AUTOSAR XML (schema 00046)
package /ComponentTypes
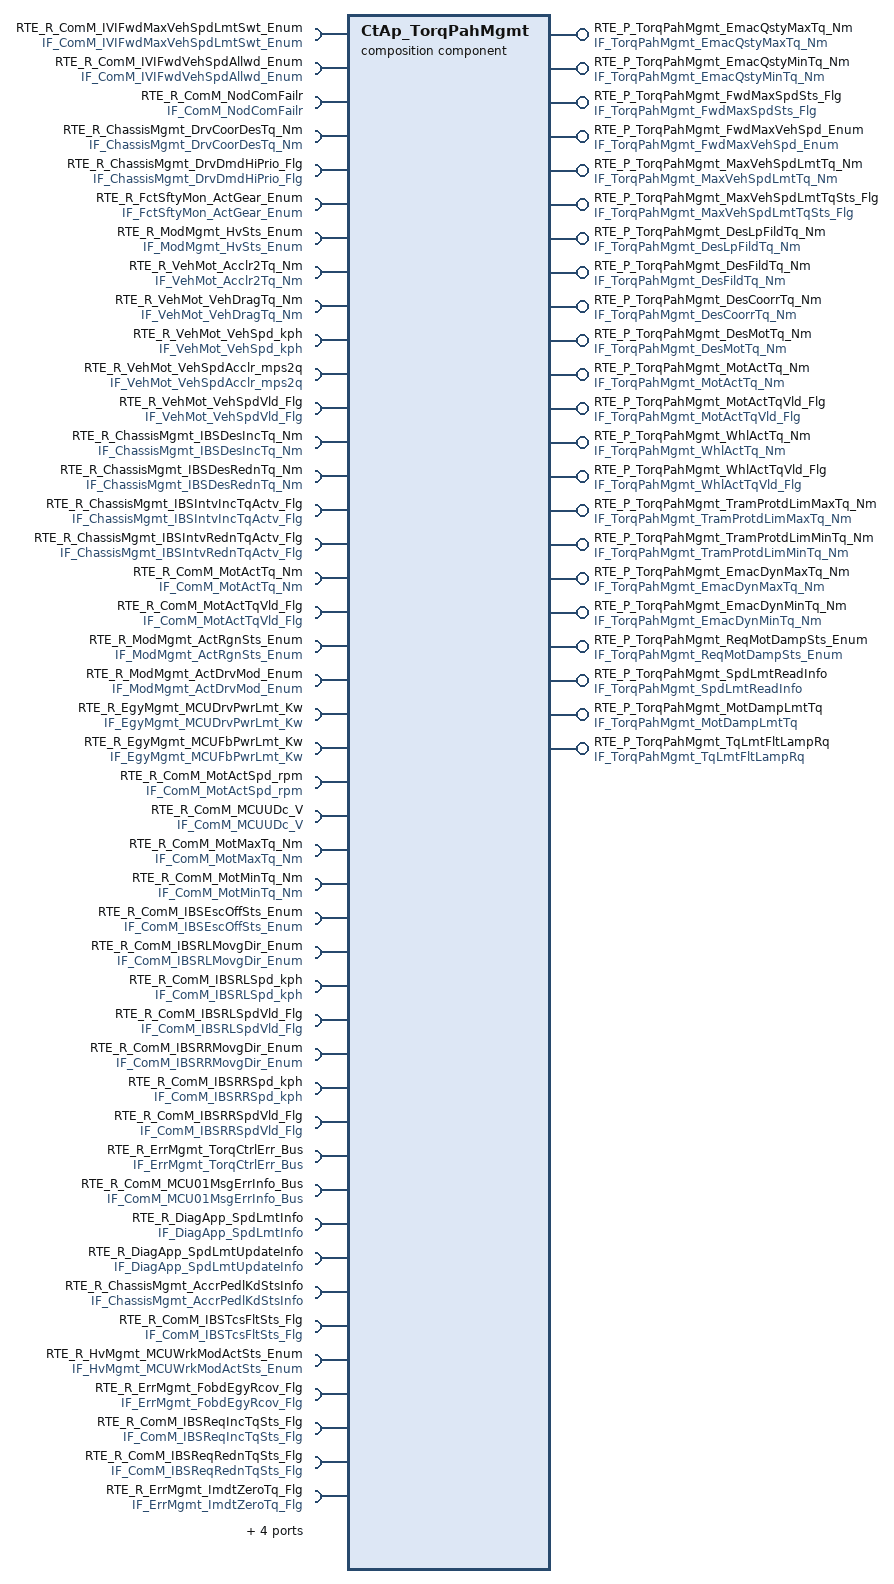
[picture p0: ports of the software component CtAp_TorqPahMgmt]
  composition sw component type CtAp_TorqPahMgmt
    require port RTE_R_ComM_IVIFwdMaxVehSpdLmtSwt_Enum: nonqueued-receiver-com-spec{data-element=tec_ComM_IVIFwdMaxVehSpdLmtSwt_Enum, filter=data-filter-type=ALWAYS, init-value=0}, required-interface=IF_ComM_IVIFwdMaxVehSpdLmtSwt_Enum
    require port RTE_R_ComM_IVIFwdVehSpdAllwd_Enum: nonqueued-receiver-com-spec{data-element=tec_ComM_IVIFwdVehSpdAllwd_Enum, filter=data-filter-type=ALWAYS, init-value=0}, required-interface=IF_ComM_IVIFwdVehSpdAllwd_Enum
    require port RTE_R_ComM_NodComFailr: required-interface=IF_ComM_NodComFailr
      required-com-specs:
        data-element=tec_ComM_SGWNodComFailr_Flg, filter=data-filter-type=ALWAYS, init-value=0
        data-element=tec_ComM_CGWNodComFailr_Flg, filter=data-filter-type=ALWAYS, init-value=0
        data-element=tec_ComM_TCUNodComFailr_Flg, filter=data-filter-type=ALWAYS, init-value=0
        data-element=tec_ComM_BCMNodComFailr_Flg, filter=data-filter-type=ALWAYS, init-value=0
        data-element=tec_ComM_PRNDNodComFailr_Flg, filter=data-filter-type=ALWAYS, init-value=0
        data-element=tec_ComM_IVINodComFailr_Flg, filter=data-filter-type=ALWAYS, init-value=0
        data-element=tec_ComM_DCDCNodComFailr_Flg, filter=data-filter-type=ALWAYS, init-value=0
        data-element=tec_ComM_OBCNodComFailr_Flg, filter=data-filter-type=ALWAYS, init-value=0
        data-element=tec_ComM_CHIBSNodComFailr_Flg, filter=data-filter-type=ALWAYS, init-value=0
        data-element=tec_ComM_MCUNodComFailr_Flg, filter=data-filter-type=ALWAYS, init-value=0
        data-element=tec_ComM_EVCOMNodComFailr_Flg, filter=data-filter-type=ALWAYS, init-value=0
        data-element=tec_ComM_EPTIBSNodComFailr_Flg, filter=data-filter-type=ALWAYS, init-value=0
        data-element=tec_ComM_DCMNodComFailr_Flg, filter=data-filter-type=ALWAYS, init-value=0
        data-element=tec_ComM_BMSNodComFailr_Flg, filter=data-filter-type=ALWAYS, init-value=0
        data-element=tec_ComM_ACUNodComFailr_Flg, filter=data-filter-type=ALWAYS, init-value=0
        data-element=tec_ComM_APTCNodComFailr_Flg, filter=data-filter-type=ALWAYS, init-value=0
        data-element=tec_ComM_ADCUNodComFailr_Flg, filter=data-filter-type=ALWAYS, init-value=0
        data-element=tec_ComM_DCMRRNodComFailr_Flg, filter=data-filter-type=ALWAYS, init-value=0
        data-element=tec_ComM_DCMRLNodComFailr_Flg, filter=data-filter-type=ALWAYS, init-value=0
        data-element=tec_ComM_DCMFRNodComFailr_Flg, filter=data-filter-type=ALWAYS, init-value=0
        data-element=tec_ComM_DCMFLNodComFailr_Flg, filter=data-filter-type=ALWAYS, init-value=0
        data-element=tec_ComM_SGWCHNodComFailr_Flg, filter=data-filter-type=ALWAYS, init-value=0
    7 x provide port:
      RTE_P_TorqPahMgmt_EmacQstyMaxTq_Nm: nonqueued-sender-com-spec{data-element=tec_TorqPahMgmt_EmacQstyMaxTq_Nm, init-value=0}, provided-interface=IF_TorqPahMgmt_EmacQstyMaxTq_Nm
      RTE_P_TorqPahMgmt_EmacQstyMinTq_Nm: nonqueued-sender-com-spec{data-element=tec_TorqPahMgmt_EmacQstyMinTq_Nm, init-value=0}, provided-interface=IF_TorqPahMgmt_EmacQstyMinTq_Nm
      RTE_P_TorqPahMgmt_FwdMaxSpdSts_Flg: nonqueued-sender-com-spec{data-element=tec_TorqPahMgmt_FwdMaxSpdSts_Flg, init-value=0}, provided-interface=IF_TorqPahMgmt_FwdMaxSpdSts_Flg
      RTE_P_TorqPahMgmt_FwdMaxVehSpd_Enum: nonqueued-sender-com-spec{data-element=tec_TorqPahMgmt_FwdMaxVehSpd_Enum, init-value=0}, provided-interface=IF_TorqPahMgmt_FwdMaxVehSpd_Enum
      RTE_P_TorqPahMgmt_MaxVehSpdLmtTq_Nm: nonqueued-sender-com-spec{data-element=tec_TorqPahMgmt_MaxVehSpdLmtTq_Nm, init-value=0}, provided-interface=IF_TorqPahMgmt_MaxVehSpdLmtTq_Nm
      RTE_P_TorqPahMgmt_MaxVehSpdLmtTqSts_Flg: nonqueued-sender-com-spec{data-element=tec_TorqPahMgmt_MaxVehSpdLmtTqSts_Flg, init-value=0}, provided-interface=IF_TorqPahMgmt_MaxVehSpdLmtTqSts_Flg
      RTE_P_TorqPahMgmt_DesLpFildTq_Nm: nonqueued-sender-com-spec{data-element=tec_TorqPahMgmt_DesLpFildTq_Nm, init-value=0}, provided-interface=IF_TorqPahMgmt_DesLpFildTq_Nm
    9 x require port:
      RTE_R_ChassisMgmt_DrvCoorDesTq_Nm: nonqueued-receiver-com-spec{data-element=tec_ChassisMgmt_DrvCoorrDesTq_Nm, filter=data-filter-type=ALWAYS, init-value=0}, required-interface=IF_ChassisMgmt_DrvCoorDesTq_Nm
      RTE_R_ChassisMgmt_DrvDmdHiPrio_Flg: nonqueued-receiver-com-spec{data-element=tec_ChassisMgmt_DrvDmdHiPrio_Flg, filter=data-filter-type=ALWAYS, init-value=0}, required-interface=IF_ChassisMgmt_DrvDmdHiPrio_Flg
      RTE_R_FctSftyMon_ActGear_Enum: nonqueued-receiver-com-spec{data-element=tec_FctSftyMon_ActGear_Enum, filter=data-filter-type=ALWAYS, init-value=0}, required-interface=IF_FctSftyMon_ActGear_Enum
      RTE_R_ModMgmt_HvSts_Enum: nonqueued-receiver-com-spec{data-element=tec_ModMgmt_HvSts_Enum, filter=data-filter-type=ALWAYS, init-value=0}, required-interface=IF_ModMgmt_HvSts_Enum
      RTE_R_VehMot_Acclr2Tq_Nm: nonqueued-receiver-com-spec{data-element=tec_VehMot_Acclr2Tq_Nm, filter=data-filter-type=ALWAYS, init-value=0}, required-interface=IF_VehMot_Acclr2Tq_Nm
      RTE_R_VehMot_VehDragTq_Nm: nonqueued-receiver-com-spec{data-element=tec_VehMot_VehDragTq_Nm, filter=data-filter-type=ALWAYS, init-value=0}, required-interface=IF_VehMot_VehDragTq_Nm
      RTE_R_VehMot_VehSpd_kph: nonqueued-receiver-com-spec{data-element=tec_VehMot_VehSpd_kph, filter=data-filter-type=ALWAYS, init-value=0}, required-interface=IF_VehMot_VehSpd_kph
      RTE_R_VehMot_VehSpdAcclr_mps2q: nonqueued-receiver-com-spec{data-element=tec_VehMot_VehSpdAcclr_mps2q, filter=data-filter-type=ALWAYS, init-value=0}, required-interface=IF_VehMot_VehSpdAcclr_mps2q
      RTE_R_VehMot_VehSpdVld_Flg: nonqueued-receiver-com-spec{data-element=tec_VehMot_VehSpdVld_Flg, filter=data-filter-type=ALWAYS, init-value=0}, required-interface=IF_VehMot_VehSpdVld_Flg
    provide port RTE_P_TorqPahMgmt_DesFildTq_Nm: nonqueued-sender-com-spec{data-element=tec_TorqPahMgmt_DesFildTq_Nm, init-value=0}, provided-interface=IF_TorqPahMgmt_DesFildTq_Nm
    4 x require port:
      RTE_R_ChassisMgmt_IBSDesIncTq_Nm: nonqueued-receiver-com-spec{data-element=tec_ChassisMgmt_IBSDesIncTq_Nm, filter=data-filter-type=ALWAYS, init-value=0}, required-interface=IF_ChassisMgmt_IBSDesIncTq_Nm
      RTE_R_ChassisMgmt_IBSDesRednTq_Nm: nonqueued-receiver-com-spec{data-element=tec_ChassisMgmt_IBSDesRednTq_Nm, filter=data-filter-type=ALWAYS, init-value=0}, required-interface=IF_ChassisMgmt_IBSDesRednTq_Nm
      RTE_R_ChassisMgmt_IBSIntvIncTqActv_Flg: nonqueued-receiver-com-spec{data-element=tec_ChassisMgmt_IBSIntvIncTqActv_Flg, filter=data-filter-type=ALWAYS, init-value=0}, required-interface=IF_ChassisMgmt_IBSIntvIncTqActv_Flg
      RTE_R_ChassisMgmt_IBSIntvRednTqActv_Flg: nonqueued-receiver-com-spec{data-element=tec_ChassisMgmt_IBSIntvRednTqActv_Flg, filter=data-filter-type=ALWAYS, init-value=0}, required-interface=IF_ChassisMgmt_IBSIntvRednTqActv_Flg
    provide port RTE_P_TorqPahMgmt_DesCoorrTq_Nm: nonqueued-sender-com-spec{data-element=tec_TorqPahMgmt_DesCoorrTq_Nm, init-value=0}, provided-interface=IF_TorqPahMgmt_DesCoorrTq_Nm
    4 x require port:
      RTE_R_ComM_MotActTq_Nm: nonqueued-receiver-com-spec{data-element=tec_ComM_MotActTq_Nm, filter=data-filter-type=ALWAYS, init-value=0}, required-interface=IF_ComM_MotActTq_Nm
      RTE_R_ComM_MotActTqVld_Flg: nonqueued-receiver-com-spec{data-element=tec_ComM_MotActTqVld_Flg, filter=data-filter-type=ALWAYS, init-value=0}, required-interface=IF_ComM_MotActTqVld_Flg
      RTE_R_ModMgmt_ActRgnSts_Enum: nonqueued-receiver-com-spec{data-element=tec_ModMgmt_ActRgnSts_Enum, filter=data-filter-type=ALWAYS, init-value=0}, required-interface=IF_ModMgmt_ActRgnSts_Enum
      RTE_R_ModMgmt_ActDrvMod_Enum: nonqueued-receiver-com-spec{data-element=tec_ModMgmt_ActDrvMod_Enum, filter=data-filter-type=ALWAYS, init-value=0}, required-interface=IF_ModMgmt_ActDrvMod_Enum
    5 x provide port:
      RTE_P_TorqPahMgmt_DesMotTq_Nm: nonqueued-sender-com-spec{data-element=tec_TorqPahMgmt_DesMotTq_Nm, init-value=0}, provided-interface=IF_TorqPahMgmt_DesMotTq_Nm
      RTE_P_TorqPahMgmt_MotActTq_Nm: nonqueued-sender-com-spec{data-element=tec_TorqPahMgmt_MotActTq_Nm, init-value=0}, provided-interface=IF_TorqPahMgmt_MotActTq_Nm
      RTE_P_TorqPahMgmt_MotActTqVld_Flg: nonqueued-sender-com-spec{data-element=tec_TorqPahMgmt_MotActTqVld_Flg, init-value=0}, provided-interface=IF_TorqPahMgmt_MotActTqVld_Flg
      RTE_P_TorqPahMgmt_WhlActTq_Nm: nonqueued-sender-com-spec{data-element=tec_TorqPahMgmt_WhlActTq_Nm, init-value=0}, provided-interface=IF_TorqPahMgmt_WhlActTq_Nm
      RTE_P_TorqPahMgmt_WhlActTqVld_Flg: nonqueued-sender-com-spec{data-element=tec_TorqPahMgmt_WhlActTqVld_Flg, init-value=0}, provided-interface=IF_TorqPahMgmt_WhlActTqVld_Flg
    6 x require port:
      RTE_R_EgyMgmt_MCUDrvPwrLmt_Kw: nonqueued-receiver-com-spec{data-element=tec_EgyMgmt_MCUDrvPwrLmt_Kw, filter=data-filter-type=ALWAYS, init-value=0}, required-interface=IF_EgyMgmt_MCUDrvPwrLmt_Kw
      RTE_R_EgyMgmt_MCUFbPwrLmt_Kw: nonqueued-receiver-com-spec{data-element=tec_EgyMgmt_MCUFbPwrLmt_Kw, filter=data-filter-type=ALWAYS, init-value=0}, required-interface=IF_EgyMgmt_MCUFbPwrLmt_Kw
      RTE_R_ComM_MotActSpd_rpm: nonqueued-receiver-com-spec{data-element=tec_ComM_MotActSpd_rpm, filter=data-filter-type=ALWAYS, init-value=0}, required-interface=IF_ComM_MotActSpd_rpm
      RTE_R_ComM_MCUUDc_V: nonqueued-receiver-com-spec{data-element=tec_ComM_MCUUDc_V, filter=data-filter-type=ALWAYS, init-value=0}, required-interface=IF_ComM_MCUUDc_V
      RTE_R_ComM_MotMaxTq_Nm: nonqueued-receiver-com-spec{data-element=tec_ComM_MotMaxTq_Nm, filter=data-filter-type=ALWAYS, init-value=0}, required-interface=IF_ComM_MotMaxTq_Nm
      RTE_R_ComM_MotMinTq_Nm: nonqueued-receiver-com-spec{data-element=tec_ComM_MotMinTq_Nm, filter=data-filter-type=ALWAYS, init-value=0}, required-interface=IF_ComM_MotMinTq_Nm
    5 x provide port:
      RTE_P_TorqPahMgmt_TramProtdLimMaxTq_Nm: nonqueued-sender-com-spec{data-element=tec_TorqPahMgmt_TramProtdLmtMaxTq_Nm, init-value=0}, provided-interface=IF_TorqPahMgmt_TramProtdLimMaxTq_Nm
      RTE_P_TorqPahMgmt_TramProtdLimMinTq_Nm: nonqueued-sender-com-spec{data-element=tec_TorqPahMgmt_TramProtdLmtMinTq_Nm, init-value=0}, provided-interface=IF_TorqPahMgmt_TramProtdLimMinTq_Nm
      RTE_P_TorqPahMgmt_EmacDynMaxTq_Nm: nonqueued-sender-com-spec{data-element=tec_TorqPahMgmt_EmacDynMaxTq_Nm, init-value=0}, provided-interface=IF_TorqPahMgmt_EmacDynMaxTq_Nm
      RTE_P_TorqPahMgmt_EmacDynMinTq_Nm: nonqueued-sender-com-spec{data-element=tec_TorqPahMgmt_EmacDynMinTq_Nm, init-value=0}, provided-interface=IF_TorqPahMgmt_EmacDynMinTq_Nm
      RTE_P_TorqPahMgmt_ReqMotDampSts_Enum: nonqueued-sender-com-spec{data-element=tec_TorqPahMgmt_ReqMotDampSts_Enum, init-value=0}, provided-interface=IF_TorqPahMgmt_ReqMotDampSts_Enum
    10 x require port:
      RTE_R_ComM_IBSEscOffSts_Enum: nonqueued-receiver-com-spec{data-element=tec_ComM_IBSEscOffSts_Enum, filter=data-filter-type=ALWAYS, init-value=0}, required-interface=IF_ComM_IBSEscOffSts_Enum
      RTE_R_ComM_IBSRLMovgDir_Enum: nonqueued-receiver-com-spec{data-element=tec_ComM_IBSRLMovgDir_Enum, filter=data-filter-type=ALWAYS, init-value=0}, required-interface=IF_ComM_IBSRLMovgDir_Enum
      RTE_R_ComM_IBSRLSpd_kph: nonqueued-receiver-com-spec{data-element=tec_ComM_IBSRLSpd_kph, filter=data-filter-type=ALWAYS, init-value=0}, required-interface=IF_ComM_IBSRLSpd_kph
      RTE_R_ComM_IBSRLSpdVld_Flg: nonqueued-receiver-com-spec{data-element=tec_ComM_IBSRLSpdVld_Flg, filter=data-filter-type=ALWAYS, init-value=0}, required-interface=IF_ComM_IBSRLSpdVld_Flg
      RTE_R_ComM_IBSRRMovgDir_Enum: nonqueued-receiver-com-spec{data-element=tec_ComM_IBSRRMovgDir_Enum, filter=data-filter-type=ALWAYS, init-value=0}, required-interface=IF_ComM_IBSRRMovgDir_Enum
      RTE_R_ComM_IBSRRSpd_kph: nonqueued-receiver-com-spec{data-element=tec_ComM_IBSRRSpd_kph, filter=data-filter-type=ALWAYS, init-value=0}, required-interface=IF_ComM_IBSRRSpd_kph
      RTE_R_ComM_IBSRRSpdVld_Flg: nonqueued-receiver-com-spec{data-element=tec_ComM_IBSRRSpdVld_Flg, filter=data-filter-type=ALWAYS, init-value=0}, required-interface=IF_ComM_IBSRRSpdVld_Flg
      RTE_R_ErrMgmt_TorqCtrlErr_Bus: nonqueued-receiver-com-spec{data-element=tec_ErrMgmt_TorqCtrlErr_Bus, filter=data-filter-type=ALWAYS, init-value=fields=[ErrMgmt_DlyGrdtZeroTq_Flg:0, ErrMgmt_GrdtZeroTq_Flg:0, ErrMgmt_ImdtZeroTq_Flg:0, ErrMgmt_VehSpdLim_kph:0, ErrMgmt_VehSpdLimEna_Flg:0]}, required-interface=IF_ErrMgmt_TorqCtrlErr_Bus
      RTE_R_ComM_MCU01MsgErrInfo_Bus: required-interface=IF_ComM_MCU01MsgErrInfo_Bus
        required-com-specs:
          data-element=tec_ComM_MCU01TimeoutInfo_Bus, filter=data-filter-type=ALWAYS, init-value=fields=[ComM_MonStatMCU01TimeoutInfo:0, ComM_MonResMCU01TimeoutInfo:0, ComM_ErrStatMCU01TimeoutInfo:0, ComM_ErrResMCU01TimeoutInfo:0]
          data-element=tec_ComM_MCU01CRCDTCInfo_Bus, filter=data-filter-type=ALWAYS, init-value=fields=[ComM_MonStatMCU01CRCDTCErrorInfo:0, ComM_MonResMCU01CRCDTCErrorInfo:0, ComM_ErrStatMCU01CRCDTCErrorInfo:0, ComM_ErrResMCU01CRCDTCErrorInfo:0]
          data-element=tec_ComM_MCU01CRCInfo_Bus, filter=data-filter-type=ALWAYS, init-value=fields=[ComM_MonStatMCU01CRCErrorInfo:0, ComM_MonResMCU01CRCErrorInfo:0, ComM_ErrStatMCU01CRCErrorInfo:0, ComM_ErrResMCU01CRCErrorInfo:0]
          data-element=tec_ComM_MCU01TimeoutDTCInfo_Bus, filter=data-filter-type=ALWAYS, init-value=fields=[ComM_MonStatMCU01TimeoutDTCErrorInfo:0, ComM_MonResMCU01TimeoutDTCErrorInfo:0, ComM_ErrStatMCU01TimeoutDTCErrorInfo:0, ComM_ErrResMCU01TimeoutDTCErrorInfo:0]
          data-element=tec_ComM_MCU01E2ETimeoutInfo_Bus, filter=data-filter-type=ALWAYS, init-value=fields=[ComM_MonStatMCU01E2ETimeoutInfo:0, ComM_MonResMCU01E2ETimeoutInfo:0, ComM_ErrStatMCU01E2ETimeoutInfo:0, ComM_ErrResMCU01E2ETimeoutInfo:0]
      RTE_R_DiagApp_SpdLmtInfo: nonqueued-receiver-com-spec{data-element=tec_DiagApp_SpdLmtInfo, filter=data-filter-type=ALWAYS, init-value=0}, required-interface=IF_DiagApp_SpdLmtInfo
    provide port RTE_P_TorqPahMgmt_SpdLmtReadInfo: nonqueued-sender-com-spec{data-element=tec_TorqPahMgmt_SpdLmtReadInfo, init-value=0}, provided-interface=IF_TorqPahMgmt_SpdLmtReadInfo
    4 x require port:
      RTE_R_DiagApp_SpdLmtUpdateInfo: nonqueued-receiver-com-spec{data-element=tec_DiagApp_SpdLmtUpdateInfo, filter=data-filter-type=ALWAYS, init-value=0}, required-interface=IF_DiagApp_SpdLmtUpdateInfo
      RTE_R_ChassisMgmt_AccrPedlKdStsInfo: nonqueued-receiver-com-spec{data-element=tec_ChassisMgmt_AccrPedlKdStsInfo, filter=data-filter-type=ALWAYS, init-value=0}, required-interface=IF_ChassisMgmt_AccrPedlKdStsInfo
      RTE_R_ComM_IBSTcsFltSts_Flg: nonqueued-receiver-com-spec{data-element=tec_ComM_IBSTcsFltSts_Flg, filter=data-filter-type=ALWAYS, init-value=0}, required-interface=IF_ComM_IBSTcsFltSts_Flg
      RTE_R_HvMgmt_MCUWrkModActSts_Enum: nonqueued-receiver-com-spec{data-element=tec_HvMgmt_MCUWrkModActSts_Enum, filter=data-filter-type=ALWAYS, init-value=0}, required-interface=IF_HvMgmt_MCUWrkModActSts_Enum
    provide port RTE_P_TorqPahMgmt_MotDampLmtTq: nonqueued-sender-com-spec{data-element=tec_TorqPahMgmt_MotDampLmtTq, init-value=0}, provided-interface=IF_TorqPahMgmt_MotDampLmtTq
    8 x require port:
      RTE_R_ErrMgmt_FobdEgyRcov_Flg: nonqueued-receiver-com-spec{data-element=tec_ErrMgmt_FobdEgyRcov_Flg, filter=data-filter-type=ALWAYS, init-value=0}, required-interface=IF_ErrMgmt_FobdEgyRcov_Flg
      RTE_R_ComM_IBSReqIncTqSts_Flg: nonqueued-receiver-com-spec{data-element=tec_ComM_IBSReqIncTqSts_Flg, filter=data-filter-type=ALWAYS, init-value=0}, required-interface=IF_ComM_IBSReqIncTqSts_Flg
      RTE_R_ComM_IBSReqRednTqSts_Flg: nonqueued-receiver-com-spec{data-element=tec_ComM_IBSReqRednTqSts_Flg, filter=data-filter-type=ALWAYS, init-value=0}, required-interface=IF_ComM_IBSReqRednTqSts_Flg
      RTE_R_ErrMgmt_ImdtZeroTq_Flg: nonqueued-receiver-com-spec{data-element=tec_ErrMgmt_ImdtZeroTq_Flg, filter=data-filter-type=ALWAYS, init-value=0}, required-interface=IF_ErrMgmt_ImdtZeroTq_Flg
      RTE_R_FctSftyMon_TarGearPInhbTq: nonqueued-receiver-com-spec{data-element=tec_FctSftyMon_TarGearPInhbTq, filter=data-filter-type=ALWAYS, init-value=0}, required-interface=IF_FctSftyMon_TarGearPInhbTq
      RTE_R_ChassisMgmt_BrkRgnActv_Flg: nonqueued-receiver-com-spec{data-element=tec_ChassisMgmt_BrkRgnActv_Flg, filter=data-filter-type=ALWAYS}, required-interface=IF_ChassisMgmt_BrkRgnActv_Flg
      RTE_R_ChassisMgmt_IBSApsReqTqActv_Flg: nonqueued-receiver-com-spec{data-element=tec_ChassisMgmt_IBSApsReqTqActv_Flg, filter=data-filter-type=ALWAYS, init-value=0}, required-interface=IF_ChassisMgmt_IBSApsReqTqActv_Flg
      RTE_R_ChassisMgmt_IBSVlcReqTqActv_Flg: nonqueued-receiver-com-spec{data-element=tec_ChassisMgmt_IBSVlcReqTqActv_Flg, filter=data-filter-type=ALWAYS, init-value=0}, required-interface=IF_ChassisMgmt_IBSVlcReqTqActv_Flg
    provide port RTE_P_TorqPahMgmt_TqLmtFltLampRq: nonqueued-sender-com-spec{data-element=tec_TorqPahMgmt_TqLmtFltLampRq, init-value=0}, provided-interface=IF_TorqPahMgmt_TqLmtFltLampRq
    8 x component:
      CtAp_SpdLmt: type=CtAp_SpdLmt
      CtAp_TorqFil: type=CtAp_TorqFil
      CtAp_TorqCrossZr: type=CtAp_TorqCrossZr
      CtAp_TorqCoor: type=CtAp_TorqCoor
      CtAp_TorqDamp: type=CtAp_TorqDamp
      CtAp_TorqModMap: type=CtAp_TorqModMap
      CtAp_TrsmProtd: type=CtAp_TrsmProtd
      CtAp_TorqLmt: type=CtAp_TorqLmt
    delegate CtAp_SpdLmt.RTE_R_ComM_IVIFwdMaxVehSpdLmtSwt_Enum <-> outer port RTE_R_ComM_IVIFwdMaxVehSpdLmtSwt_Enum
    delegate CtAp_SpdLmt.RTE_R_ComM_IVIFwdVehSpdAllwd_Enum <-> outer port RTE_R_ComM_IVIFwdVehSpdAllwd_Enum
    delegate CtAp_SpdLmt.RTE_R_ComM_NodComFailr <-> outer port RTE_R_ComM_NodComFailr
    delegate CtAp_SpdLmt.RTE_R_FctSftyMon_ActGear_Enum <-> outer port RTE_R_FctSftyMon_ActGear_Enum
    delegate CtAp_SpdLmt.RTE_R_ModMgmt_HvSts_Enum <-> outer port RTE_R_ModMgmt_HvSts_Enum
    delegate CtAp_SpdLmt.RTE_R_VehMot_VehSpd_kph <-> outer port RTE_R_VehMot_VehSpd_kph
    delegate CtAp_SpdLmt.RTE_R_VehMot_VehDragTq_Nm <-> outer port RTE_R_VehMot_VehDragTq_Nm
    delegate CtAp_SpdLmt.RTE_R_VehMot_VehSpdVld_Flg <-> outer port RTE_R_VehMot_VehSpdVld_Flg
    delegate CtAp_SpdLmt.RTE_R_VehMot_Acclr2Tq_Nm <-> outer port RTE_R_VehMot_Acclr2Tq_Nm
    delegate CtAp_SpdLmt.RTE_R_VehMot_VehSpdAcclr_mps2q <-> outer port RTE_R_VehMot_VehSpdAcclr_mps2q
    delegate CtAp_SpdLmt.RTE_P_TorqPahMgmt_FwdMaxSpdSts_Flg <-> outer port RTE_P_TorqPahMgmt_FwdMaxSpdSts_Flg
    delegate CtAp_SpdLmt.RTE_P_TorqPahMgmt_FwdMaxVehSpd_Enum <-> outer port RTE_P_TorqPahMgmt_FwdMaxVehSpd_Enum
    delegate CtAp_SpdLmt.RTE_P_TorqPahMgmt_MaxVehSpdLmtTq_Nm <-> outer port RTE_P_TorqPahMgmt_MaxVehSpdLmtTq_Nm
    delegate CtAp_SpdLmt.RTE_P_TorqPahMgmt_MaxVehSpdLmtTqSts_Flg <-> outer port RTE_P_TorqPahMgmt_MaxVehSpdLmtTqSts_Flg
    delegate CtAp_TorqFil.RTE_R_ChassisMgmt_DrvCoorDesTq_Nm <-> outer port RTE_R_ChassisMgmt_DrvCoorDesTq_Nm
    delegate CtAp_TorqFil.RTE_R_ChassisMgmt_DrvDmdHiPrio_Flg <-> outer port RTE_R_ChassisMgmt_DrvDmdHiPrio_Flg
    delegate CtAp_TorqFil.RTE_P_TorqPahMgmt_DesLpFildTq_Nm <-> outer port RTE_P_TorqPahMgmt_DesLpFildTq_Nm
    delegate CtAp_TorqCrossZr.RTE_R_ChassisMgmt_DrvDmdHiPrio_Flg <-> outer port RTE_R_ChassisMgmt_DrvDmdHiPrio_Flg
    delegate CtAp_TorqCrossZr.RTE_R_ModMgmt_ActDrvMod_Enum <-> outer port RTE_R_ModMgmt_ActDrvMod_Enum
    delegate CtAp_TorqCrossZr.RTE_R_FctSftyMon_ActGear_Enum <-> outer port RTE_R_FctSftyMon_ActGear_Enum
    connect CtAp_TorqFil.RTE_P_TorqPahMgmt_DesLpFildTq_Nm -> CtAp_TorqCrossZr.RTE_R_TorqPahMgmt_DesLpFildTq_Nm
    delegate CtAp_TorqCrossZr.RTE_R_ModMgmt_ActRgnSts_Enum <-> outer port RTE_R_ModMgmt_ActRgnSts_Enum
    delegate CtAp_TorqCrossZr.RTE_R_VehMot_VehSpd_kph <-> outer port RTE_R_VehMot_VehSpd_kph
    delegate CtAp_TorqCoor.RTE_R_ChassisMgmt_IBSDesIncTq_Nm <-> outer port RTE_R_ChassisMgmt_IBSDesIncTq_Nm
    delegate CtAp_TorqCoor.RTE_R_ChassisMgmt_IBSIntvIncTqActv_Flg <-> outer port RTE_R_ChassisMgmt_IBSIntvIncTqActv_Flg
    delegate CtAp_TorqCoor.RTE_R_ChassisMgmt_IBSDesRednTq_Nm <-> outer port RTE_R_ChassisMgmt_IBSDesRednTq_Nm
    delegate CtAp_TorqCoor.RTE_R_ModMgmt_HvSts_Enum <-> outer port RTE_R_ModMgmt_HvSts_Enum
    delegate CtAp_TorqCoor.RTE_R_ChassisMgmt_IBSIntvRednTqActv_Flg <-> outer port RTE_R_ChassisMgmt_IBSIntvRednTqActv_Flg
    delegate CtAp_TorqCoor.RTE_R_VehMot_VehSpd_kph <-> outer port RTE_R_VehMot_VehSpd_kph
    connect CtAp_TorqCrossZr.RTE_P_TorqPahMgmt_DesFildTq_Nm -> CtAp_TorqCoor.RTE_R_TorqPahMgmt_DesFildTq_Nm
    delegate CtAp_TorqModMap.RTE_P_TorqPahMgmt_DesMotTq_Nm <-> outer port RTE_P_TorqPahMgmt_DesMotTq_Nm
    delegate CtAp_TorqModMap.RTE_P_TorqPahMgmt_MotActTq_Nm <-> outer port RTE_P_TorqPahMgmt_MotActTq_Nm
    delegate CtAp_TorqModMap.RTE_P_TorqPahMgmt_MotActTqVld_Flg <-> outer port RTE_P_TorqPahMgmt_MotActTqVld_Flg
    delegate CtAp_TorqModMap.RTE_P_TorqPahMgmt_WhlActTqVld_Flg <-> outer port RTE_P_TorqPahMgmt_WhlActTqVld_Flg
    delegate CtAp_TorqModMap.RTE_P_TorqPahMgmt_WhlActTq_Nm <-> outer port RTE_P_TorqPahMgmt_WhlActTq_Nm
    connect CtAp_TorqCoor.RTE_P_TorqPahMgmt_DesCoorrTq_Nm -> CtAp_TorqModMap.RTE_R_TorqPahMgmt_DesCoorrTq_Nm
    delegate CtAp_TorqModMap.RTE_R_ComM_MotActTq_Nm <-> outer port RTE_R_ComM_MotActTq_Nm
    delegate CtAp_TorqModMap.RTE_R_FctSftyMon_ActGear_Enum <-> outer port RTE_R_FctSftyMon_ActGear_Enum
    delegate CtAp_TorqModMap.RTE_R_ComM_MotActTqVld_Flg <-> outer port RTE_R_ComM_MotActTqVld_Flg
    delegate CtAp_TorqModMap.RTE_R_ModMgmt_HvSts_Enum <-> outer port RTE_R_ModMgmt_HvSts_Enum
    delegate CtAp_TorqLmt.RTE_P_TorqPahMgmt_EmacQstyMaxTq_Nm <-> outer port RTE_P_TorqPahMgmt_EmacQstyMaxTq_Nm
    delegate CtAp_TorqLmt.RTE_P_TorqPahMgmt_EmacQstyMinTq_Nm <-> outer port RTE_P_TorqPahMgmt_EmacQstyMinTq_Nm
    delegate CtAp_TorqLmt.RTE_P_TorqPahMgmt_EmacDynMaxTq_Nm <-> outer port RTE_P_TorqPahMgmt_EmacDynMaxTq_Nm
    delegate CtAp_TorqLmt.RTE_P_TorqPahMgmt_EmacDynMinTq_Nm <-> outer port RTE_P_TorqPahMgmt_EmacDynMinTq_Nm
    connect CtAp_TorqLmt.RTE_P_TorqPahMgmt_EmacDynMinTq_Nm -> CtAp_TorqModMap.RTE_R_TorqPahMgmt_EmacDynMinTq_Nm
    connect CtAp_TorqLmt.RTE_P_TorqPahMgmt_EmacDynMaxTq_Nm -> CtAp_TorqModMap.RTE_R_TorqPahMgmt_EmacDynMaxTq_Nm
    connect CtAp_TorqLmt.RTE_P_TorqPahMgmt_EmacQstyMaxTq_Nm -> CtAp_TorqFil.RTE_R_TorqPhMgmt_EmacQstyMaxTq_Nm
    connect CtAp_TorqLmt.RTE_P_TorqPahMgmt_EmacQstyMinTq_Nm -> CtAp_TorqFil.RTE_R_TorqPhMgmt_EmacQstyMinTq_Nm
    connect CtAp_TorqLmt.RTE_P_TorqPahMgmt_EmacQstyMaxTq_Nm -> CtAp_SpdLmt.RTE_R_TorqPahMgmt_EmacQstyMaxTq_Nm
    connect CtAp_TorqLmt.RTE_P_TorqPahMgmt_EmacQstyMinTq_Nm -> CtAp_SpdLmt.RTE_R_TorqPahMgmt_EmacQstyMinTq_Nm
    delegate CtAp_TorqLmt.RTE_R_EgyMgmt_MCUDrvPwrLmt_Kw <-> outer port RTE_R_EgyMgmt_MCUDrvPwrLmt_Kw
    delegate CtAp_TorqLmt.RTE_R_EgyMgmt_MCUFbPwrLmt_Kw <-> outer port RTE_R_EgyMgmt_MCUFbPwrLmt_Kw
    delegate CtAp_TorqLmt.RTE_R_ComM_MotActSpd_rpm <-> outer port RTE_R_ComM_MotActSpd_rpm
    delegate CtAp_TorqLmt.RTE_R_ComM_MCUUDc_V <-> outer port RTE_R_ComM_MCUUDc_V
    delegate CtAp_TorqLmt.RTE_R_ComM_MotMaxTq_Nm <-> outer port RTE_R_ComM_MotMaxTq_Nm
    delegate CtAp_TorqLmt.RTE_R_ComM_MotMinTq_Nm <-> outer port RTE_R_ComM_MotMinTq_Nm
    delegate CtAp_TrsmProtd.RTE_P_TorqPahMgmt_TramProtdLimMinTq_Nm <-> outer port RTE_P_TorqPahMgmt_TramProtdLimMinTq_Nm
    delegate CtAp_TrsmProtd.RTE_P_TorqPahMgmt_TramProtdLimMaxTq_Nm <-> outer port RTE_P_TorqPahMgmt_TramProtdLimMaxTq_Nm
    delegate CtAp_TrsmProtd.RTE_R_ComM_IBSEscOffSts_Enum <-> outer port RTE_R_ComM_IBSEscOffSts_Enum
    delegate CtAp_TrsmProtd.RTE_R_ComM_IBSRRSpd_kph <-> outer port RTE_R_ComM_IBSRRSpd_kph
    delegate CtAp_TrsmProtd.RTE_R_ComM_IBSRRSpdVld_Flg <-> outer port RTE_R_ComM_IBSRRSpdVld_Flg
    delegate CtAp_TrsmProtd.RTE_R_ComM_IBSRLMovgDir_Enum <-> outer port RTE_R_ComM_IBSRLMovgDir_Enum
    delegate CtAp_TrsmProtd.RTE_R_ComM_IBSRLSpd_kph <-> outer port RTE_R_ComM_IBSRLSpd_kph
    delegate CtAp_TrsmProtd.RTE_R_ComM_IBSRRMovgDir_Enum <-> outer port RTE_R_ComM_IBSRRMovgDir_Enum
    delegate CtAp_TrsmProtd.RTE_R_ComM_IBSRLSpdVld_Flg <-> outer port RTE_R_ComM_IBSRLSpdVld_Flg
    delegate CtAp_TrsmProtd.RTE_R_FctSftyMon_ActGear_Enum <-> outer port RTE_R_FctSftyMon_ActGear_Enum
    delegate CtAp_TorqDamp.RTE_P_TorqPahMgmt_ReqMotDampSts_Enum <-> outer port RTE_P_TorqPahMgmt_ReqMotDampSts_Enum
    delegate CtAp_TorqCrossZr.RTE_P_TorqPahMgmt_DesFildTq_Nm <-> outer port RTE_P_TorqPahMgmt_DesFildTq_Nm
    delegate CtAp_TorqDamp.RTE_R_ModMgmt_HvSts_Enum <-> outer port RTE_R_ModMgmt_HvSts_Enum
    delegate CtAp_TorqDamp.RTE_R_FctSftyMon_ActGear_Enum <-> outer port RTE_R_FctSftyMon_ActGear_Enum
    connect CtAp_TrsmProtd.RTE_P_TorqPahMgmt_TramProtdLimMaxTq_Nm -> CtAp_TorqLmt.RTE_R_TorqPahMgmt_TramProtdLimMaxTq_Nm
    connect CtAp_TrsmProtd.RTE_P_TorqPahMgmt_TramProtdLimMinTq_Nm -> CtAp_TorqLmt.RTE_R_TorqPahMgmt_TramProtdLimMinTq_Nm
    connect CtAp_TorqLmt.RTE_P_TorqPahMgmt_EmacQstyMaxTq_Nm -> CtAp_TorqCoor.RTE_R_TorqPahMgmt_EmacQstyMaxTq_Nm
    connect CtAp_TorqLmt.RTE_P_TorqPahMgmt_EmacQstyMinTq_Nm -> CtAp_TorqCoor.RTE_R_TorqPahMgmt_EmacQstyMinTq_Nm
    delegate CtAp_SpdLmt.RTE_R_ErrMgmt_TorqCtrlErr_Bus <-> outer port RTE_R_ErrMgmt_TorqCtrlErr_Bus
    delegate CtAp_TorqCoor.RTE_P_TorqPahMgmt_DesCoorrTq_Nm <-> outer port RTE_P_TorqPahMgmt_DesCoorrTq_Nm
    delegate CtAp_TorqLmt.RTE_R_ErrMgmt_TorqCtrlErr_Bus <-> outer port RTE_R_ErrMgmt_TorqCtrlErr_Bus
    delegate CtAp_TorqModMap.RTE_R_ComM_MCU01MsgErrInfo_Bus <-> outer port RTE_R_ComM_MCU01MsgErrInfo_Bus
    delegate CtAp_TorqLmt.RTE_R_FctSftyMon_ActGear_Enum <-> outer port RTE_R_FctSftyMon_ActGear_Enum
    delegate CtAp_TorqLmt.RTE_R_ComM_MotActTq_Nm <-> outer port RTE_R_ComM_MotActTq_Nm
    delegate CtAp_SpdLmt.RTE_R_DiagApp_SpdLmtInfo <-> outer port RTE_R_DiagApp_SpdLmtInfo
    delegate CtAp_SpdLmt.RTE_P_TorqPahMgmt_SpdLmtReadInfo <-> outer port RTE_P_TorqPahMgmt_SpdLmtReadInfo
    delegate CtAp_SpdLmt.RTE_R_DiagApp_SpdLmtUpdateInfo <-> outer port RTE_R_DiagApp_SpdLmtUpdateInfo
    delegate CtAp_SpdLmt.RTE_R_ChassisMgmt_AccrPedlKdStsInfo <-> outer port RTE_R_ChassisMgmt_AccrPedlKdStsInfo
    delegate CtAp_TrsmProtd.RTE_R_ComM_IBSTcsFltSts_Flg <-> outer port RTE_R_ComM_IBSTcsFltSts_Flg
    delegate CtAp_TorqLmt.RTE_R_HvMgmt_MCUWrkModActSts_Enum <-> outer port RTE_R_HvMgmt_MCUWrkModActSts_Enum
    delegate CtAp_TorqDamp.RTE_P_TorqPahMgmt_MotDampLmtTq <-> outer port RTE_P_TorqPahMgmt_MotDampLmtTq
    connect CtAp_TrsmProtd.RTE_P_TorqPahMgmt_MotDftlProtnActv -> CtAp_TorqDamp.RTE_R_TorqPahMgmt_MotDftlProtnActv
    delegate CtAp_SpdLmt.RTE_R_ErrMgmt_FobdEgyRcov_Flg <-> outer port RTE_R_ErrMgmt_FobdEgyRcov_Flg
    delegate CtAp_TorqDamp.RTE_R_ComM_IBSReqIncTqSts_Flg <-> outer port RTE_R_ComM_IBSReqIncTqSts_Flg
    delegate CtAp_TorqDamp.RTE_R_ComM_IBSReqRednTqSts_Flg <-> outer port RTE_R_ComM_IBSReqRednTqSts_Flg
    delegate CtAp_TorqDamp.RTE_R_ErrMgmt_ImdtZeroTq_Flg <-> outer port RTE_R_ErrMgmt_ImdtZeroTq_Flg
    delegate CtAp_TorqLmt.RTE_R_ErrMgmt_FobdEgyRcov_Flg <-> outer port RTE_R_ErrMgmt_FobdEgyRcov_Flg
    delegate CtAp_TorqLmt.RTE_R_FctSftyMon_TarGearPInhbTq <-> outer port RTE_R_FctSftyMon_TarGearPInhbTq
    connect CtAp_TrsmProtd.RTE_P_TorqPahMgmt_MotDftlProtnActv -> CtAp_TorqLmt.RTE_R_TorqPahMgmt_MotDftlProtnActv
    delegate CtAp_TorqCrossZr.RTE_R_ChassisMgmt_BrkRgnActv_Flg <-> outer port RTE_R_ChassisMgmt_BrkRgnActv_Flg
    delegate CtAp_TorqCrossZr.RTE_R_ChassisMgmt_IBSApsReqTqActv_Flg <-> outer port RTE_R_ChassisMgmt_IBSApsReqTqActv_Flg
    delegate CtAp_TorqCrossZr.RTE_R_ChassisMgmt_IBSVlcReqTqActv_Flg <-> outer port RTE_R_ChassisMgmt_IBSVlcReqTqActv_Flg
    delegate CtAp_TorqModMap.RTE_P_TorqPahMgmt_TqLmtFltLampRq <-> outer port RTE_P_TorqPahMgmt_TqLmtFltLampRq
